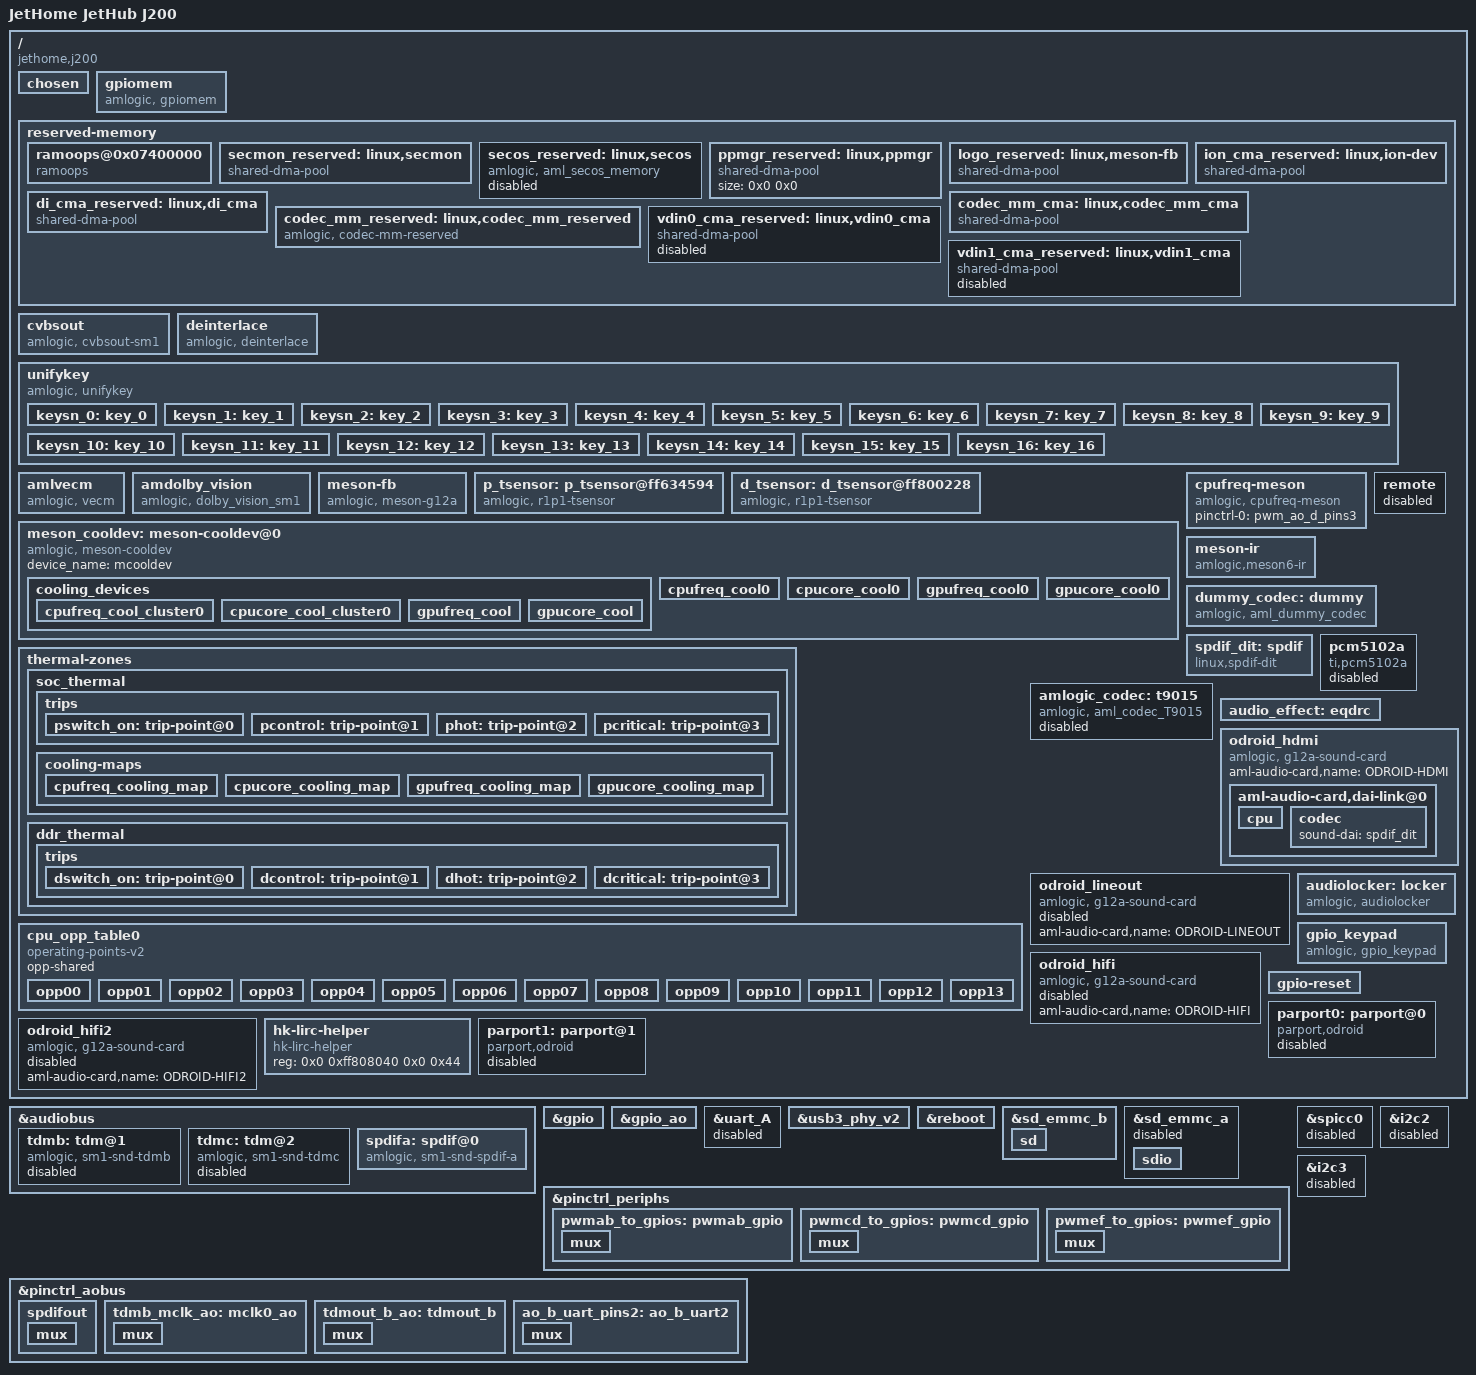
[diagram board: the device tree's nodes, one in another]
/*
 * arch/arm64/boot/dts/amlogic/meson64_odroidc4.dts
 *
 * Copyright (C) 2019 Hardkernel Co., Ltd. All rights reserved.
 *
 * This program is free software; you can redistribute it and/or modify
 * it under the terms of the GNU General Public License as published by
 * the Free Software Foundation; either version 2 of the License, or
 * (at your option) any later version.
 *
 * This program is distributed in the hope that it will be useful, but WITHOUT
 * ANY WARRANTY; without even the implied warranty of MERCHANTABILITY or
 * FITNESS FOR A PARTICULAR PURPOSE.  See the GNU General Public License for
 * more details.
 *
 */

/dts-v1/;

#include "mesonsm1.dtsi"
#include "mesong12_odroid_common.dtsi"
#include "partition.dtsi"

/ {
	compatible = "jethome,j200", "amlogic,meson-sm1", "amlogic,meson-g12a";
	model = "JetHome JetHub J200";
	amlogic-dt-id = "sm1_jethubj200_v1";
	interrupt-parent = <&gic>;
	#address-cells = <2>;
	#size-cells = <2>;

	chosen { };

	gpiomem {
		compatible = "amlogic, gpiomem";
		reg = <0x0 0xff634000 0x0 0x1000>,	/* GPIO banks */
			<0x0 0xff800000 0x0 0x1000>;	/* GPIO_AO bank */
		status = "okay";
	};

	reserved-memory {
		#address-cells = <2>;
		#size-cells = <2>;
		ranges;
		/* global autoconfigured region for contiguous allocations */
		ramoops@0x07400000 {
			compatible = "ramoops";
			reg = <0x0 0x07400000 0x0 0x00100000>;
			record-size = <0x8000>;
			console-size = <0x8000>;
			ftrace-size = <0x20000>;
		};

		secmon_reserved:linux,secmon {
			compatible = "shared-dma-pool";
			reusable;
			size = <0x0 0x400000>;
			alignment = <0x0 0x400000>;
			alloc-ranges = <0x0 0x05000000 0x0 0x400000>;
			clear-map;
		};

		secos_reserved:linux,secos {
			status = "disable";
			compatible = "amlogic, aml_secos_memory";
			reg = <0x0 0x05300000 0x0 0x2000000>;
			no-map;
		};

		/*  POST PROCESS MANAGER */
		ppmgr_reserved:linux,ppmgr {
			compatible = "shared-dma-pool";
			size = <0x0 0x0>;
		};

		logo_reserved:linux,meson-fb {
			compatible = "shared-dma-pool";
			reusable;
			size = <0x0 0x800000>;
			alignment = <0x0 0x400000>;
			alloc-ranges = <0x0 0x7f800000 0x0 0x800000>;
		};
		ion_cma_reserved:linux,ion-dev {
			compatible = "shared-dma-pool";
			reusable;
			size = <0x0 0x8000000>;
			alignment = <0x0 0x400000>;
		};

		//di_reserved:linux,di {
			//compatible = "amlogic, di-mem";
			/* buffer_size = 3621952(yuv422 8bit) */
			/* 4179008(yuv422 10bit full pack mode) */
			/** 10x3621952=34.6M(0x23) support 8bit **/
			/** 10x4736064=45.2M(0x2e) support 12bit **/
			/** 10x4179008=40M(0x28) support 10bit **/
			//size = <0x0 0x2800000>;
			//no-map;
		//};
		/*di CMA pool */
		di_cma_reserved:linux,di_cma {
			compatible = "shared-dma-pool";
			reusable;
			/* buffer_size = 3621952(yuv422 8bit)
			 *  | 4736064(yuv422 10bit)
			 *  | 4074560(yuv422 10bit full pack mode)
			 * 10x3621952=34.6M(0x23) support 8bit
			 * 10x4736064=45.2M(0x2e) support 12bit
			 * 10x4074560=40M(0x28) support 10bit
			 */
			size = <0x0 0x02800000>;
			alignment = <0x0 0x400000>;
		};
		codec_mm_cma:linux,codec_mm_cma {
			compatible = "shared-dma-pool";
			reusable;
			/* ion_codec_mm max can alloc size 80M*/
			size = <0x0 0x13400000>;
			alignment = <0x0 0x400000>;
			linux,contiguous-region;
			clear-map;
		};
		/* codec shared reserved */
		codec_mm_reserved:linux,codec_mm_reserved {
			compatible = "amlogic, codec-mm-reserved";
			size = <0x0 0x0>;
			alignment = <0x0 0x100000>;
			//no-map;
		};
		/*  vdin0 CMA pool */
		vdin0_cma_reserved:linux,vdin0_cma {
			status = "disable";
			compatible = "shared-dma-pool";
			reusable;
			/* 1920x1080x2x4  =16+4 M */
			size = <0x0 0x04000000>;
			alignment = <0x0 0x400000>;
		};
		/*  vdin1 CMA pool */
		vdin1_cma_reserved:linux,vdin1_cma {
			status = "disable";
			compatible = "shared-dma-pool";
			reusable;
			/* 1920x1080x2x4  =16 M */
			size = <0x0 0x04000000>;
			alignment = <0x0 0x400000>;
		};
	};

	cvbsout {
		compatible = "amlogic, cvbsout-sm1";
		dev_name = "cvbsout";
		status = "okay";
		clocks = <&clkc CLKID_VCLK2_ENCI
			&clkc CLKID_VCLK2_VENCI0
			&clkc CLKID_VCLK2_VENCI1
			&clkc CLKID_DAC_CLK>;
		clock-names = "venci_top_gate",
			"venci_0_gate",
			"venci_1_gate",
			"vdac_clk_gate";
		/* clk path */
		/* 0:vid_pll vid2_clk */
		/* 1:gp0_pll vid2_clk */
		/* 2:vid_pll vid1_clk */
		/* 3:gp0_pll vid1_clk */
		clk_path = <0>;

		/* performance: reg_address, reg_value */
		/* sm1 */
		performance = <0x1bf0  0x9
			0x1b56  0x333
			0x1b12  0x8080
			0x1b05  0xfd
			0x1c59  0xf850
			0xffff  0x0>; /* ending flag */
		performance_sarft = <0x1bf0  0x9
			0x1b56  0x333
			0x1b12  0x0
			0x1b05  0x9
			0x1c59  0xfc48
			0xffff  0x0>; /* ending flag */
		performance_revB_telecom = <0x1bf0  0x9
			0x1b56  0x546
			0x1b12  0x8080
			0x1b05  0x9
			0x1c59  0xf850
			0xffff  0x0>; /* ending flag */
	};

	deinterlace {
		compatible = "amlogic, deinterlace";
		status = "okay";
		/* 0:use reserved; 1:use cma; 2:use cma as reserved */
		flag_cma = <1>;
		//memory-region = <&di_reserved>;
		memory-region = <&di_cma_reserved>;
		interrupts = <0 46 1
				0 40 1>;
		interrupt-names = "pre_irq", "post_irq";
		clocks = <&clkc CLKID_VPU_CLKB_TMP_COMP>,
			<&clkc CLKID_VPU_CLKB_COMP>;
		clock-names = "vpu_clkb_tmp_composite",
			"vpu_clkb_composite";
		clock-range = <334 667>;
		/* buffer-size = <3621952>;(yuv422 8bit) */
		buffer-size = <4074560>;/*yuv422 fullpack*/
		/* reserve-iomap = "true"; */
		/* if enable nr10bit, set nr10bit-support to 1 */
		post-wr-support = <1>;
		nr10bit-support = <1>;
		nrds-enable = <1>;
		pps-enable = <1>;
	};

	unifykey{
		compatible = "amlogic, unifykey";
		status = "ok";
		unifykey-num = <14>;
		unifykey-index-0 = <&keysn_0>;
		unifykey-index-1 = <&keysn_1>;
		unifykey-index-2 = <&keysn_2>;
		unifykey-index-3 = <&keysn_3>;
		unifykey-index-4 = <&keysn_4>;
		unifykey-index-5 = <&keysn_5>;
		unifykey-index-6 = <&keysn_6>;
		unifykey-index-7 = <&keysn_7>;
		unifykey-index-8 = <&keysn_8>;
		unifykey-index-9 = <&keysn_9>;
		unifykey-index-10= <&keysn_10>;
		unifykey-index-11= <&keysn_11>;
		unifykey-index-12= <&keysn_12>;
		unifykey-index-13= <&keysn_13>;
		unifykey-index-14= <&keysn_14>;
		unifykey-index-15= <&keysn_15>;
		unifykey-index-16= <&keysn_16>;

		keysn_0: key_0{
			key-name = "usid";
			key-device = "normal";
			key-permit = "read","write","del";
		};
		keysn_1:key_1{
			key-name = "mac";
			key-device = "normal";
			key-permit = "read","write","del";
		};
		keysn_2:key_2{
			key-name = "hdcp";
			key-device = "secure";
			key-type = "sha1";
			key-permit = "read","write","del";
		};
		keysn_3:key_3{
			key-name = "secure_boot_set";
			key-device = "efuse";
			key-permit = "write";
		};
		keysn_4:key_4{
			key-name = "mac_bt";
			key-device = "normal";
			key-permit = "read","write","del";
			key-type  = "mac";
		};
		keysn_5:key_5{
			key-name = "mac_wifi";
			key-device = "normal";
			key-permit = "read","write","del";
			key-type = "mac";
		};
		keysn_6:key_6{
			key-name = "hdcp2_tx";
			key-device = "normal";
			key-permit = "read","write","del";
		};
		keysn_7:key_7{
			key-name = "hdcp2_rx";
			key-device = "normal";
			key-permit = "read","write","del";
		};
		keysn_8:key_8{
			key-name = "widevinekeybox";
			key-device = "secure";
			key-permit = "read","write","del";
		};
		keysn_9:key_9{
			key-name = "deviceid";
			key-device = "normal";
			key-permit = "read","write","del";
		};
		keysn_10:key_10{
			key-name = "hdcp22_fw_private";
			key-device = "secure";
			key-permit = "read","write","del";
		};
		keysn_11:key_11{
			key-name = "PlayReadykeybox25";
			key-device = "secure";
			key-permit = "read","write","del";
		};
		keysn_12:key_12{
			key-name = "prpubkeybox";// PlayReady
			key-device = "secure";
			key-permit = "read","write","del";
		};
		keysn_13:key_13{
			key-name = "prprivkeybox";// PlayReady
			key-device = "secure";
			key-permit = "read","write","del";
		};
		keysn_14:key_14{
			key-name = "attestationkeybox";// attestation key
			key-device = "secure";
			key-permit = "read","write","del";
		};
		keysn_15:key_15{
			key-name = "region_code";
			key-device = "normal";
			key-permit = "read","write","del";
		};
		keysn_16:key_16{
			key-name = "netflix_mgkid";
			key-device = "secure";
			key-permit = "read","write","del";
		};
	};//End unifykey

	amlvecm {
		compatible = "amlogic, vecm";
		dev_name = "aml_vecm";
		status = "okay";
		gamma_en = <0>;/*1:enabel ;0:disable*/
		wb_en = <0>;/*1:enabel ;0:disable*/
		cm_en = <0>;/*1:enabel ;0:disable*/
		/*0: 709/601  1: bt2020*/
		tx_op_color_primary = <0>;
	};

	amdolby_vision {
		compatible = "amlogic, dolby_vision_sm1";
		dev_name = "aml_amdolby_vision_driver";
		status = "okay";
		tv_mode = <0>;/*1:enabel ;0:disable*/
	};

	meson-fb {
		compatible = "amlogic, meson-g12a";
		/*memory-region = <&logo_reserved>;*/
		dev_name = "meson-fb";
		status = "okay";
		interrupts = <0 3 1
			0 56 1
			0 89 1>;
		interrupt-names = "viu-vsync", "viu2-vsync", "rdma";
		mem_size = <0x00800000 0x4b80000 0x100000 0x100000 0x800000>;
		/* uboot logo,fb0/fb1 memory size,if afbcd fb0=0x01851000*/
		display_mode_default = "1080p60hz";
		scale_mode = <1>;
		/** 0:VPU free scale 1:OSD free scale 2:OSD super scale */
		display_size_default = <1920 1080 1920 2160 32>;
		/*1920*1080*4*3 = 0x17BB000*/
		pxp_mode = <0>; /** 0:normal mode 1:pxp mode */
		mem_alloc = <1>;
		4k2k_fb = <1>;
		logo_addr = "0x3f800000";
		clocks = <&clkc CLKID_VPU_CLKC_MUX>;
		clock-names = "vpu_clkc";
	};

	p_tsensor: p_tsensor@ff634594 {
		compatible = "amlogic, r1p1-tsensor";
		device_name = "meson-pthermal";
		status = "okay";
		reg = <0x0 0xff634800 0x0 0x50>,
			<0x0 0xff800268 0x0 0x4>;
		cal_type = <0x1>;
		cal_a = <324>;
		cal_b = <424>;
		cal_c = <3159>;
		cal_d = <9411>;
		rtemp = <115000>;
		interrupts = <0 35 0>;
		clocks = <&clkc CLKID_TS_COMP>; /* CLKID_TS_COMP>;*/
		clock-names = "ts_comp";
		#thermal-sensor-cells = <1>;
	};

	d_tsensor: d_tsensor@ff800228 {
		compatible = "amlogic, r1p1-tsensor";
		device_name = "meson-dthermal";
		status = "okay";
		reg = <0x0 0xff634c00 0x0 0x50>,
			<0x0 0xff800230 0x0 0x4>;
		cal_type = <0x1>;
		cal_a = <324>;
		cal_b = <424>;
		cal_c = <3159>;
		cal_d = <9411>;
		rtemp = <115000>;
		interrupts = <0 36 0>;
		clocks = <&clkc CLKID_TS_COMP>; /* CLKID_TS_COMP>;*/
		clock-names = "ts_comp";
		#thermal-sensor-cells = <1>;
	};

	meson_cooldev: meson-cooldev@0 {
			status = "okay";
			compatible = "amlogic, meson-cooldev";
			device_name = "mcooldev";
			cooling_devices {
				cpufreq_cool_cluster0 {
					min_state = <1000000>;
					dyn_coeff = <125>;
					cluster_id = <0>;
					node_name = "cpufreq_cool0";
					device_type = "cpufreq";
				};
				cpucore_cool_cluster0 {
					min_state = <1>;
					dyn_coeff = <0>;
					cluster_id = <0>;
					node_name = "cpucore_cool0";
					device_type = "cpucore";
				};
				gpufreq_cool {
					min_state = <400>;
					dyn_coeff = <215>;
					gpu_pp = <2>;
					cluster_id = <0>;
					node_name = "gpufreq_cool0";
					device_type = "gpufreq";
				};
				gpucore_cool {
					min_state = <1>;
					dyn_coeff = <0>;
					cluster_id = <0>;
					node_name = "gpucore_cool0";
					device_type = "gpucore";
				};
			};
			cpufreq_cool0:cpufreq_cool0 {
				#cooling-cells = <2>; /* min followed by max */
			};
			cpucore_cool0:cpucore_cool0 {
				#cooling-cells = <2>; /* min followed by max */
			};
			gpufreq_cool0:gpufreq_cool0 {
				#cooling-cells = <2>; /* min followed by max */
			};
			gpucore_cool0:gpucore_cool0 {
				#cooling-cells = <2>; /* min followed by max */
			};
		};
		/*meson cooling devices end*/

	thermal-zones {
		soc_thermal: soc_thermal {
			polling-delay = <1000>;
			polling-delay-passive = <100>;
			sustainable-power = <1410>;
			thermal-sensors = <&p_tsensor 0>;
			trips {
				pswitch_on: trip-point@0 {
					temperature = <60000>;
					hysteresis = <5000>;
					type = "passive";
				};
				pcontrol: trip-point@1 {
					temperature = <75000>;
					hysteresis = <5000>;
					type = "passive";
				};
				phot: trip-point@2 {
					temperature = <85000>;
					hysteresis = <5000>;
					type = "hot";
				};
				pcritical: trip-point@3 {
					temperature = <110000>;
					hysteresis = <1000>;
					type = "critical";
				};
			};

			cooling-maps {
				cpufreq_cooling_map {
					trip = <&pcontrol>;
					cooling-device = <&cpufreq_cool0 0 4>;
					contribution = <1024>;
				};
				cpucore_cooling_map {
					trip = <&pcontrol>;
					cooling-device = <&cpucore_cool0 0 3>;
					contribution = <1024>;
				};
				gpufreq_cooling_map {
					trip = <&pcontrol>;
					cooling-device = <&gpufreq_cool0 0 4>;
					contribution = <1024>;
				};
				gpucore_cooling_map {
					trip = <&pcontrol>;
					cooling-device = <&gpucore_cool0 0 2>;
					contribution = <1024>;
				};
			};
		};
		ddr_thermal: ddr_thermal {
			polling-delay = <2000>;
			polling-delay-passive = <1000>;
			sustainable-power = <1410>;
			thermal-sensors = <&d_tsensor 1>;
			trips {
				dswitch_on: trip-point@0 {
					temperature = <60000>;
					hysteresis = <5000>;
					type = "passive";
				};
				dcontrol: trip-point@1 {
					temperature = <75000>;
					hysteresis = <5000>;
					type = "passive";
				};
				dhot: trip-point@2 {
					temperature = <85000>;
					hysteresis = <5000>;
					type = "hot";
				};
				dcritical: trip-point@3 {
					temperature = <110000>;
					hysteresis = <1000>;
					type = "critical";
				};
			};

		};
	};
	/*thermal zone end*/

	cpu_opp_table0: cpu_opp_table0 {
		compatible = "operating-points-v2";
		opp-shared;

		opp00 {
			opp-hz = /bits/ 64 <100000000>;
			opp-microvolt = <760000>;
		};
		opp01 {
			opp-hz = /bits/ 64 <250000000>;
			opp-microvolt = <760000>;
		};
		opp02 {
			opp-hz = /bits/ 64 <500000000>;
			opp-microvolt = <760000>;
		};
		opp03 {
			opp-hz = /bits/ 64 <667000000>;
			opp-microvolt = <780000>;
		};
		opp04 {
			opp-hz = /bits/ 64 <1000000000>;
			opp-microvolt = <800000>;
		};
		opp05 {
			opp-hz = /bits/ 64 <1200000000>;
			opp-microvolt = <810000>;
		};
		opp06 {
			opp-hz = /bits/ 64 <1404000000>;
			opp-microvolt = <820000>;
		};
		opp07 {
			opp-hz = /bits/ 64 <1500000000>;
			opp-microvolt = <830000>;
		};
		opp08 {
			opp-hz = /bits/ 64 <1608000000>;
			opp-microvolt = <860000>;
		};
		opp09 {
			opp-hz = /bits/ 64 <1704000000>;
			opp-microvolt = <900000>;
		};
		opp10 {
			opp-hz = /bits/ 64 <1800000000>;
			opp-microvolt = <940000>;
		};
		opp11 {
			opp-hz = /bits/ 64 <1908000000>;
			opp-microvolt = <1000000>;
		};
		opp12 {
			opp-hz = /bits/ 64 <2016000000>;
			opp-microvolt = <1010000>;
		};
		opp13 {
			opp-hz = /bits/ 64 <2100000000>;
			opp-microvolt = <1030000>;
		};
	};

	cpufreq-meson {
		compatible = "amlogic, cpufreq-meson";
		pinctrl-names = "default";
		pinctrl-0 = <&pwm_ao_d_pins3>;
		status = "okay";
	};

	remote {
		status = "disabled";
	};

	meson-ir {
		compatible = "amlogic,meson6-ir";
		/* Multi-format IR controller */
		reg = <0x0 0xff808040 0x0 0x44>;
		interrupts = <0 196 1>;
		pinctrl-names = "default";
		pinctrl-0 = <&remote_pins>;
		pulse-inverted;
		status = "ok";
	};

	/* Audio Related start */
	dummy_codec:dummy{
		#sound-dai-cells = <0>;
		compatible = "amlogic, aml_dummy_codec";
		status = "okay";
	};
	spdif_dit:spdif{
		#sound-dai-cells = <0>;
		compatible = "linux,spdif-dit";
		status = "okay";
	};
	pcm5102a: pcm5102a {
		compatible = "ti,pcm5102a";
		#sound-dai-cells = <0>;
		status = "disabled";
	};
	amlogic_codec:t9015{
		#sound-dai-cells = <0>;
		compatible = "amlogic, aml_codec_T9015";
		reg = <0x0 0xFF632000 0x0 0x2000>;
		is_auge_used = <1>; /* meson or auge chipset used */
		tocodec_inout = <1>;
		tdmout_index = <2>;
		ch0_sel = <0>;
		ch1_sel = <1>;
		status = "disabled";
	};
	audio_effect:eqdrc{
		/*eq_enable = <1>;*/
		/*drc_enable = <1>;*/
		/*
		 * 0:tdmout_a
		 * 1:tdmout_b
		 * 2:tdmout_c
		 * 3:spdifout
		 * 4:spdifout_b
		 */
		eqdrc_module = <1>;
		/* max 0xf, each bit for one lane, usually one lane */
		lane_mask = <0x1>;
		/* max 0xff, each bit for one channel */
		channel_mask = <0x3>;
	};
	odroid_hdmi: odroid_hdmi{
		compatible = "amlogic, g12a-sound-card";
		aml-audio-card,name = "ODROID-HDMI";

		/* ODROID-C4: spdif_out GPIOAO_10(J7.2), HDMI out*/
		aml-audio-card,dai-link@0 {
			mclk-fs = <128>;
			continuous-clock;
			cpu {
				sound-dai = <&spdifa>;
				system-clock-frequency = <6144000>;
			};
			codec {
				sound-dai = <&spdif_dit>;
			};
		};
	};
	odroid_lineout: odroid_lineout {
		compatible = "amlogic, g12a-sound-card";
		aml-audio-card,name = "ODROID-LINEOUT";
		status = "disabled";
	};
	odroid_hifi: odroid_hifi {
		compatible = "amlogic, g12a-sound-card";
		aml-audio-card,name = "ODROID-HIFI";
		status = "disabled";
	};
	odroid_hifi2: odroid_hifi2 {
		compatible = "amlogic, g12a-sound-card";
		aml-audio-card,name = "ODROID-HIFI2";
		status = "disabled";
	};

	audiolocker: locker {
		compatible = "amlogic, audiolocker";
		clocks = <&clkaudio CLKID_AUDIO_LOCKER_OUT
				&clkaudio CLKID_AUDIO_LOCKER_IN
				&clkaudio CLKID_AUDIO_MCLK_D
				&clkaudio CLKID_AUDIO_MCLK_E
				&clkc CLKID_MPLL1
				&clkc CLKID_MPLL2>;
		clock-names = "lock_out", "lock_in", "out_src",
					"in_src", "out_calc", "in_ref";
		interrupts = <GIC_SPI 1 IRQ_TYPE_EDGE_RISING>;
		interrupt-names = "irq";
		frequency = <49000000>; /* pll */
		dividor = <49>; /* locker's parent */
		status = "okay";
	};
	/* Audio Related end */

	gpio_keypad{
		compatible = "amlogic, gpio_keypad";
		status = "okay";
		scan_period = <20>;
		key_num = <1>;
		key_name = "power";
		key_code = <116>;
		reg = <0x0 0xFF800000 0x0 0x400>;
	};

	hk-lirc-helper {
		compatible = "hk-lirc-helper";
		/* Multi-format IR controller */
		reg = <0x0 0xff808040 0x0 0x44>;
		status = "ok";
	};

	gpio-reset {
		/delete-node/ usb_hub_en;
	};

	parport0: parport@0 {
		  compatible = "parport,odroid";
		  status = "disabled";
	};

	parport1: parport@1 {
		  compatible = "parport,odroid";
		  status = "disabled";
	};
}; /* end of / */

&audiobus {
	tdmb: tdm@1 {
		compatible = "amlogic, sm1-snd-tdmb";
		#sound-dai-cells = <0>;
		dai-tdm-lane-slot-mask-in = <0 1 0 0>;
		dai-tdm-lane-slot-mask-out = <1 0 0 0>;
		dai-tdm-clk-sel = <1>;
		clocks = <&clkaudio CLKID_AUDIO_MCLK_B
				&clkaudio CLKID_AUDIO_MCLK_PAD0
				&clkc CLKID_MPLL0>;
		clock-names = "mclk", "mclk_pad", "clk_srcpll";
		pinctrl-names = "tdm_pins";
		pinctrl-0 = <&tdmb_mclk_ao &tdmout_b_ao>;
		i2s2hdmi = <0>;
		/*enable default mclk(12.288M), before extern codec start*/
		start_clk_enable = <1>;
		/*tdm clk tuning enable*/
		clk_tuning_enable = <1>;
		status = "disabled";
	};

	tdmc: tdm@2 {
		compatible = "amlogic, sm1-snd-tdmc";
		#sound-dai-cells = <0>;
		dai-tdm-lane-slot-mask-in = <0 1 0 0>;
		dai-tdm-lane-slot-mask-out = <1 0 0 0>;
		dai-tdm-clk-sel = <2>;
		clocks = <&clkaudio CLKID_AUDIO_MCLK_C
				&clkc CLKID_MPLL2>;
		clock-names = "mclk", "clk_srcpll";
		i2s2hdmi = <0>;
		status = "disabled";
	};

	spdifa: spdif@0 {
		compatible = "amlogic, sm1-snd-spdif-a";
		#sound-dai-cells = <0>;
		clocks = <&clkc CLKID_MPLL0
				&clkc CLKID_FCLK_DIV4
				&clkaudio CLKID_AUDIO_GATE_SPDIFIN
				&clkaudio CLKID_AUDIO_GATE_SPDIFOUT_A
				&clkaudio CLKID_AUDIO_SPDIFIN
				&clkaudio CLKID_AUDIO_SPDIFOUT_A>;
		clock-names = "sysclk", "fixed_clk", "gate_spdifin",
				"gate_spdifout", "clk_spdifin", "clk_spdifout";
		interrupts =
				<GIC_SPI 151 IRQ_TYPE_EDGE_RISING>;

		interrupt-names = "irq_spdifin";
		pinctrl-names = "spdif_pins";
		pinctrl-0 = <&spdifout>;

		status = "okay";
	};
}; /* end of audiobus */

&gpio {
	gpio-line-names =
		/* GPIOV */
		"",
		/* GPIOZ */
		"", "", "", "", "", "", "", "",
		"", "", "", "", "", "", "", "",
		/* GPIOH */
		"", "", "", "", "",
		"PIN_36", /* GPIOH_5 */
		"PIN_26", /* GPIOH_6 */
		"PIN_32", /* GPIOH_7 */
		"",
		/* BOOT */
		"", "", "", "", "", "", "", "",
		"", "", "", "", "", "", "", "",
		/* GPIOC */
		"", "", "", "", "", "", "", "",
		/* GPIOA */
		"", "", "", "", "", "", "", "",
		"", "", "", "", "", "",
		"PIN_27", /* GPIOA_14 */
		"PIN_28", /* GPIOA_15 */
		/* GPIOX */
		"PIN_16", /* GPIOX_0 */
		"PIN_18", /* GPIOX_1 */
		"PIN_22", /* GPIOX_2 */
		"PIN_11", /* GPIOX_3 */
		"PIN_13", /* GPIOX_4 */
		"PIN_7",  /* GPIOX_5 */
		"PIN_33", /* GPIOX_6 */
		"PIN_15", /* GPIOX_7 */
		"PIN_19", /* GPIOX_8 */
		"PIN_21", /* GPIOX_9 */
		"PIN_24", /* GPIOX_10 */
		"PIN_23", /* GPIOX_11 */
		"PIN_8",  /* GPIOX_12 */
		"PIN_10", /* GPIOX_13 */
		"PIN_29", /* GPIOX_14 */
		"PIN_31", /* GPIOX_15 */
		"PIN_12", /* GPIOX_16 */
		"PIN_3",  /* GPIOX_17 */
		"PIN_5",  /* GPIOX_18 */
		"PIN_35"; /* GPIOX_19 */
};

&gpio_ao {
	gpio-line-names =
		/* GPIOAO */
		"", "", "", "",
		"PIN_47", /* GPIOAO_4 */
		"", "",
		"PIN_45", /* GPIOAO_7 */
		"PIN_46", /* GPIOAO_8 */
		"PIN_44", /* GPIOAO_9 */
		"PIN_42", /* GPIOAO_10 */
		"",
		/* GPIOE */
		"", "", "",
		/* GPIO_TEST_N */
		"";
};

&uart_A {
	status = "disabled";
};

&usb3_phy_v2 {
	status = "okay";
	portnum = <1>;
	otg = <1>;
	gpio-vbus-power = "GPIOAO_2";
	gpios = <&gpio_ao GPIOAO_2 GPIO_ACTIVE_HIGH>;
};

&reboot {
	sd_volsw_gpio = <&gpio_ao GPIOAO_6 GPIO_ACTIVE_HIGH>;
	sd_power_gpio = <&gpio_ao GPIOAO_3 GPIO_ACTIVE_HIGH>;
	sd_vddio_gpio = <&gpio_ao GPIOE_2 GPIO_ACTIVE_HIGH>;
};

&sd_emmc_b {
	status = "okay";
	sd-uhs-sdr25;
	sd-uhs-sdr50;
	sd-uhs-sdr104;
	max-frequency = <200000000>;
	sd {
		caps = "MMC_CAP_4_BIT_DATA",
			"MMC_CAP_UHS_SDR25",
			"MMC_CAP_UHS_SDR50",
			"MMC_CAP_UHS_SDR104",
			"MMC_CAP_MMC_HIGHSPEED",
			"MMC_CAP_SD_HIGHSPEED",
			"MMC_CAP_ERASE",
			"MMC_CAP_CMD23";
		vol_switch = <&gpio_ao GPIOAO_6 GPIO_ACTIVE_HIGH>;
		vol_switch_18 = <1>;
		f_min = <400000>;
		f_max = <200000000>;
	};
};

&sd_emmc_a {
	status = "disabled";
	sdio {
		caps = "MMC_CAP_4_BIT_DATA",
			 "MMC_CAP_MMC_HIGHSPEED",
			 "MMC_CAP_SD_HIGHSPEED",
			 "MMC_CAP_NONREMOVABLE",
			 "MMC_CAP_UHS_SDR12",
			 "MMC_CAP_UHS_SDR25",
			 "MMC_CAP_UHS_SDR50",
			 "MMC_CAP_UHS_SDR104",
			 "MMC_PM_KEEP_POWER",
			 "MMC_CAP_SDIO_IRQ";
		f_min = <400000>;
		f_max = <200000000>;
	};
};

&pinctrl_periphs {
	pwmab_to_gpios: pwmab_gpio {
		mux {
			groups = "GPIOX_6", "GPIOX_19";
			function = "gpio_periphs";
		};
	};

	pwmcd_to_gpios: pwmcd_gpio {
		mux {
			groups = "GPIOX_5", "GPIOX_3";
			function = "gpio_periphs";
		};
	};

	pwmef_to_gpios: pwmef_gpio {
		mux {
			groups = "GPIOX_16", "GPIOX_7";
			function = "gpio_periphs";
		};
	};
};

&pinctrl_aobus {
	spdifout: spdifout {
		mux {/* GPIOAO_10 */
			groups = "spdif_out_ao";
			function = "spdif_out_ao";
		};
	};
	tdmb_mclk_ao: mclk0_ao {
		mux { /* GPIOAO_9 */
			groups = "mclk0_ao";
			function = "mclk0_ao";
			drive-strength = <2>;
		};
	};
	tdmout_b_ao: tdmout_b {
		mux { /* GPIOAO_8, GPIOAO_7, GPIOAO_4 */
			groups = "tdmb_sclk_ao",
				"tdmb_fs_ao",
				"tdmb_dout0_ao";
			function = "tdmb_out_ao";
			drive-strength = <2>;
		};
	};
	ao_b_uart_pins2: ao_b_uart2 {
		mux { /* GPIOAO_8, GPIOAO_9 */
			groups = "uart_ao_tx_b_8",
				"uart_ao_rx_b_9";
			function = "uart_ao_b";
		};
	};
}; /* end of pinctrl_aobus */

&spicc0 {
	status = "disabled";

	/*
	 40 Pin Header : MOSI(GPIOX.8->19 Pin), MISO(GPIOX.9->21 Pin),
			 SPI0_CLK(GPIOX.11->23 Pin)
			 SPI_CE0(GPIOX.2->22 Pin), SPI_CE1(GPIOX.10->24 Pin)
	*/
	pinctrl-names = "default","gpio_periphs";
	pinctrl-0 = <&spicc0_pins_x>;
	pinctrl-1 = <&spicc0_to_gpiox>;
	num_chipselect = <2>;

	cs-gpios = <&gpio GPIOX_10 GPIO_ACTIVE_LOW>,
		   <&gpio GPIOH_6 GPIO_ACTIVE_LOW>;
};

&i2c2 {
	status = "disabled";
};

&i2c3 {
	status = "disabled";
};
